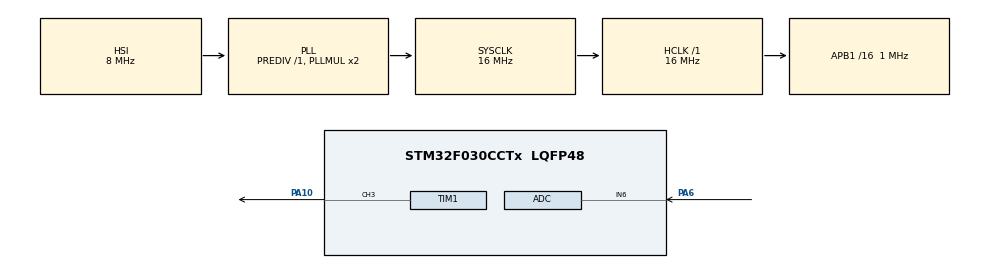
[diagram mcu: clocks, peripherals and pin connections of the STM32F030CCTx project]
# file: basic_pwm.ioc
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Mcu.Family=STM32F0
Mcu.Name=STM32F030CCTx
Mcu.Package=LQFP48
PA10.Signal=S_TIM1_CH3
PA13.Mode=Serial_Wire
PA13.Signal=SYS_SWDIO
PA14.Mode=Serial_Wire
PA14.Signal=SYS_SWCLK
PA6.Mode=IN6
PA6.Signal=ADC_IN6
ProjectManager.HeapSize=0x200
ProjectManager.StackSize=0x400
ProjectManager.TargetToolchain=STM32CubeIDE
RCC.AHBFreq_Value=16000000
RCC.APB1CLKDivider=RCC_HCLK_DIV16
RCC.APB1Freq_Value=1000000
RCC.APB1TimFreq_Value=2000000
RCC.HCLKFreq_Value=16000000
RCC.SYSCLKFreq_VALUE=16000000
RCC.SYSCLKSource=RCC_SYSCLKSOURCE_PLLCLK
SH.S_TIM1_CH3.0=TIM1_CH3,PWM Generation3 CH3
TIM1.Channel-PWM\ Generation3\ CH3=TIM_CHANNEL_3
TIM1.Period=100-1
TIM1.Pulse-PWM\ Generation3\ CH3=10-1
VP_TIM1_VS_ClockSourceINT.Mode=Internal
board=custom

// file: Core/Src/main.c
/* USER CODE BEGIN Header */
/**
  ******************************************************************************
  * @file           : main.c
  * @brief          : Main program body
  ******************************************************************************
  * @attention
  *
  * Copyright (c) 2024 STMicroelectronics.
  * All rights reserved.
  *
  * This software is licensed under terms that can be found in the LICENSE file
  * in the root directory of this software component.
  * If no LICENSE file comes with this software, it is provided AS-IS.
  *
  ******************************************************************************
  */
/* USER CODE END Header */
#include "main.h"

ADC_HandleTypeDef hadc;

TIM_HandleTypeDef htim1;

/* USER CODE BEGIN PV */
uint16_t duty = 0;
/* USER CODE END PV */

void SystemClock_Config(void);
static void MX_GPIO_Init(void);
static void MX_TIM1_Init(void);
static void MX_ADC_Init(void);

int main(void)
{

  /* MCU Configuration--------------------------------------------------------*/

  /* Reset of all peripherals, Initializes the Flash interface and the Systick. */
  HAL_Init();

  /* Configure the system clock */
  SystemClock_Config();

  /* Initialize all configured peripherals */
  MX_GPIO_Init();
  MX_TIM1_Init();
  MX_ADC_Init();
  /* USER CODE BEGIN 2 */
  HAL_TIM_PWM_Start(&htim1, TIM_CHANNEL_3);
  /* USER CODE END 2 */

  /* Infinite loop */
  while (1)
  {
	  HAL_ADC_Start(&hadc);

	  HAL_ADC_PollForConversion(&hadc, HAL_MAX_DELAY);

	  uint16_t adcRawData = HAL_ADC_GetValue(&hadc);

	  float mvData = ( ( (float)adcRawData / 4096.0 ) * 3300 ); // mV

	  HAL_Delay(100);

	  duty = ( mvData / 3300.0 )*99; // PWM duty-Cycle

	  htim1.Instance->CCR3 = duty; // Pulse width
  }
}

void SystemClock_Config(void)
{
  RCC_OscInitTypeDef RCC_OscInitStruct = {0};
  RCC_ClkInitTypeDef RCC_ClkInitStruct = {0};

  /** Initializes the RCC Oscillators according to the specified parameters
  * in the RCC_OscInitTypeDef structure.
  */
  RCC_OscInitStruct.OscillatorType = RCC_OSCILLATORTYPE_HSI|RCC_OSCILLATORTYPE_HSI14;
  RCC_OscInitStruct.HSIState = RCC_HSI_ON;
  RCC_OscInitStruct.HSI14State = RCC_HSI14_ON;
  RCC_OscInitStruct.HSICalibrationValue = RCC_HSICALIBRATION_DEFAULT;
  RCC_OscInitStruct.HSI14CalibrationValue = 16;
  RCC_OscInitStruct.PLL.PLLState = RCC_PLL_ON;
  RCC_OscInitStruct.PLL.PLLSource = RCC_PLLSOURCE_HSI;
  RCC_OscInitStruct.PLL.PLLMUL = RCC_PLL_MUL2;
  RCC_OscInitStruct.PLL.PREDIV = RCC_PREDIV_DIV1;
  if (HAL_RCC_OscConfig(&RCC_OscInitStruct) != HAL_OK)
  {
    Error_Handler();
  }

  /** Initializes the CPU, AHB and APB buses clocks
  */
  RCC_ClkInitStruct.ClockType = RCC_CLOCKTYPE_HCLK|RCC_CLOCKTYPE_SYSCLK
                              |RCC_CLOCKTYPE_PCLK1;
  RCC_ClkInitStruct.SYSCLKSource = RCC_SYSCLKSOURCE_PLLCLK;
  RCC_ClkInitStruct.AHBCLKDivider = RCC_SYSCLK_DIV1;
  RCC_ClkInitStruct.APB1CLKDivider = RCC_HCLK_DIV16;

  if (HAL_RCC_ClockConfig(&RCC_ClkInitStruct, FLASH_LATENCY_0) != HAL_OK)
  {
    Error_Handler();
  }
}

static void MX_ADC_Init(void)
{

  ADC_ChannelConfTypeDef sConfig = {0};

  /** Configure the global features of the ADC (Clock, Resolution, Data Alignment and number of conversion)
  */
  hadc.Instance = ADC1;
  hadc.Init.ClockPrescaler = ADC_CLOCK_ASYNC_DIV1;
  hadc.Init.Resolution = ADC_RESOLUTION_12B;
  hadc.Init.DataAlign = ADC_DATAALIGN_RIGHT;
  hadc.Init.ScanConvMode = ADC_SCAN_DIRECTION_FORWARD;
  hadc.Init.EOCSelection = ADC_EOC_SINGLE_CONV;
  hadc.Init.LowPowerAutoWait = DISABLE;
  hadc.Init.LowPowerAutoPowerOff = DISABLE;
  hadc.Init.ContinuousConvMode = DISABLE;
  hadc.Init.DiscontinuousConvMode = DISABLE;
  hadc.Init.ExternalTrigConv = ADC_SOFTWARE_START;
  hadc.Init.ExternalTrigConvEdge = ADC_EXTERNALTRIGCONVEDGE_NONE;
  hadc.Init.DMAContinuousRequests = DISABLE;
  hadc.Init.Overrun = ADC_OVR_DATA_PRESERVED;
  if (HAL_ADC_Init(&hadc) != HAL_OK)
  {
    Error_Handler();
  }

  /** Configure for the selected ADC regular channel to be converted.
  */
  sConfig.Channel = ADC_CHANNEL_6;
  sConfig.Rank = ADC_RANK_CHANNEL_NUMBER;
  sConfig.SamplingTime = ADC_SAMPLETIME_1CYCLE_5;
  if (HAL_ADC_ConfigChannel(&hadc, &sConfig) != HAL_OK)
  {
    Error_Handler();
  }

}

static void MX_TIM1_Init(void)
{

  TIM_ClockConfigTypeDef sClockSourceConfig = {0};
  TIM_MasterConfigTypeDef sMasterConfig = {0};
  TIM_OC_InitTypeDef sConfigOC = {0};
  TIM_BreakDeadTimeConfigTypeDef sBreakDeadTimeConfig = {0};

  htim1.Instance = TIM1;
  htim1.Init.Prescaler = 0;
  htim1.Init.CounterMode = TIM_COUNTERMODE_UP;
  htim1.Init.Period = 100-1;
  htim1.Init.ClockDivision = TIM_CLOCKDIVISION_DIV1;
  htim1.Init.RepetitionCounter = 0;
  htim1.Init.AutoReloadPreload = TIM_AUTORELOAD_PRELOAD_DISABLE;
  if (HAL_TIM_Base_Init(&htim1) != HAL_OK)
  {
    Error_Handler();
  }
  sClockSourceConfig.ClockSource = TIM_CLOCKSOURCE_INTERNAL;
  if (HAL_TIM_ConfigClockSource(&htim1, &sClockSourceConfig) != HAL_OK)
  {
    Error_Handler();
  }
  if (HAL_TIM_PWM_Init(&htim1) != HAL_OK)
  {
    Error_Handler();
  }
  sMasterConfig.MasterOutputTrigger = TIM_TRGO_RESET;
  sMasterConfig.MasterSlaveMode = TIM_MASTERSLAVEMODE_DISABLE;
  if (HAL_TIMEx_MasterConfigSynchronization(&htim1, &sMasterConfig) != HAL_OK)
  {
    Error_Handler();
  }
  sConfigOC.OCMode = TIM_OCMODE_PWM1;
  sConfigOC.Pulse = 10-1;
  sConfigOC.OCPolarity = TIM_OCPOLARITY_HIGH;
  sConfigOC.OCNPolarity = TIM_OCNPOLARITY_HIGH;
  sConfigOC.OCFastMode = TIM_OCFAST_DISABLE;
  sConfigOC.OCIdleState = TIM_OCIDLESTATE_RESET;
  sConfigOC.OCNIdleState = TIM_OCNIDLESTATE_RESET;
  if (HAL_TIM_PWM_ConfigChannel(&htim1, &sConfigOC, TIM_CHANNEL_3) != HAL_OK)
  {
    Error_Handler();
  }
  sBreakDeadTimeConfig.OffStateRunMode = TIM_OSSR_DISABLE;
  sBreakDeadTimeConfig.OffStateIDLEMode = TIM_OSSI_DISABLE;
  sBreakDeadTimeConfig.LockLevel = TIM_LOCKLEVEL_OFF;
  sBreakDeadTimeConfig.DeadTime = 0;
  sBreakDeadTimeConfig.BreakState = TIM_BREAK_DISABLE;
  sBreakDeadTimeConfig.BreakPolarity = TIM_BREAKPOLARITY_HIGH;
  sBreakDeadTimeConfig.AutomaticOutput = TIM_AUTOMATICOUTPUT_DISABLE;
  if (HAL_TIMEx_ConfigBreakDeadTime(&htim1, &sBreakDeadTimeConfig) != HAL_OK)
  {
    Error_Handler();
  }
  HAL_TIM_MspPostInit(&htim1);

}

static void MX_GPIO_Init(void)
{

  /* GPIO Ports Clock Enable */
  __HAL_RCC_GPIOA_CLK_ENABLE();

}

void Error_Handler(void)
{
  __disable_irq();
  while (1)
  {
  }
}
